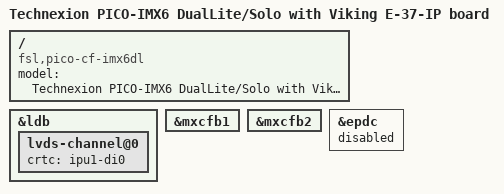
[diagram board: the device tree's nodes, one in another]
/*
 * Copyright 2018 Arcturus Networks Inc.
 *
 * This program is free software; you can redistribute it and/or modify
 * it under the terms of the GNU General Public License version 2 as
 * published by the Free Software Foundation.
 *
 */
/dts-v1/;

#include <dt-bindings/interrupt-controller/irq.h>
#include "imx6dl.dtsi"
#include "imx6qdl-viking.dtsi"
#include "baseboard_pico_viking.dtsi"
/ {
	model = "Technexion PICO-IMX6 DualLite/Solo with Viking E-37-IP board";
	compatible = "fsl,pico-cf-imx6dl", "fsl,imx6dl";
};

&ldb {
	lvds-channel@0 {
		crtc = "ipu1-di0";
	};
};

&mxcfb1 {
	status = "okay";
};

&mxcfb2 {
	status = "okay";
};

&epdc {
	status = "disabled";
};
